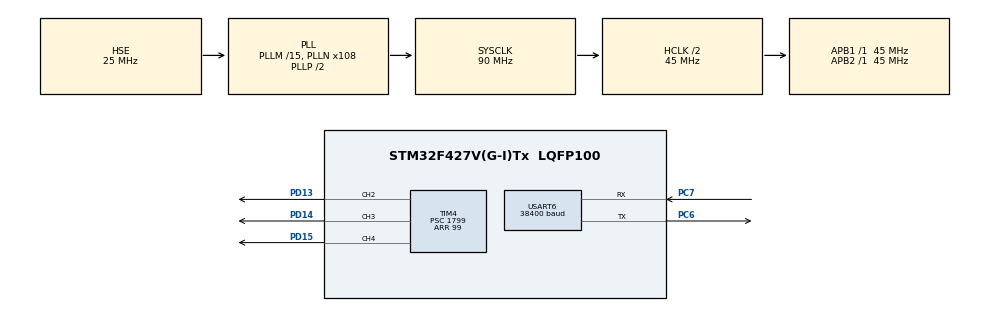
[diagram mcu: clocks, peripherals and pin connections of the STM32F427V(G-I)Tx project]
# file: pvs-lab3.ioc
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Mcu.Family=STM32F4
Mcu.Name=STM32F427V(G-I)Tx
Mcu.Package=LQFP100
NVIC.PriorityGroup=NVIC_PRIORITYGROUP_4
NVIC.USART6_IRQn=true\:0\:0\:false\:false\:true\:true\:true\:true
PC6.Mode=Asynchronous
PC6.Signal=USART6_TX
PC7.Mode=Asynchronous
PC7.Signal=USART6_RX
PD13.Signal=S_TIM4_CH2
PD14.Signal=S_TIM4_CH3
PD15.Signal=S_TIM4_CH4
PH0/OSC_IN.Mode=HSE-External-Oscillator
PH0/OSC_IN.Signal=RCC_OSC_IN
PH1/OSC_OUT.Mode=HSE-External-Oscillator
PH1/OSC_OUT.Signal=RCC_OSC_OUT
ProjectManager.HeapSize=0x200
ProjectManager.StackSize=0x400
ProjectManager.TargetToolchain=STM32CubeIDE
RCC.48MHZClocksFreq_Value=45000000
RCC.AHBCLKDivider=RCC_SYSCLK_DIV2
RCC.AHBFreq_Value=45000000
RCC.APB1Freq_Value=45000000
RCC.APB1TimFreq_Value=45000000
RCC.APB2Freq_Value=45000000
RCC.APB2TimFreq_Value=45000000
RCC.CortexFreq_Value=45000000
RCC.HCLKFreq_Value=45000000
RCC.HSE_VALUE=25000000
RCC.HSI_VALUE=16000000
RCC.LSE_VALUE=32768
RCC.PLLM=15
RCC.PLLN=108
RCC.PLLSourceVirtual=RCC_PLLSOURCE_HSE
RCC.SYSCLKFreq_VALUE=90000000
RCC.SYSCLKSource=RCC_SYSCLKSOURCE_PLLCLK
RCC.VCOOutputFreq_Value=180000000
SH.S_TIM4_CH2.0=TIM4_CH2,PWM Generation2 CH2
SH.S_TIM4_CH3.0=TIM4_CH3,PWM Generation3 CH3
SH.S_TIM4_CH4.0=TIM4_CH4,PWM Generation4 CH4
TIM4.Channel-PWM\ Generation2\ CH2=TIM_CHANNEL_2
TIM4.Channel-PWM\ Generation3\ CH3=TIM_CHANNEL_3
TIM4.Channel-PWM\ Generation4\ CH4=TIM_CHANNEL_4
TIM4.Period=99
TIM4.Prescaler=1799
USART6.BaudRate=38400
USART6.VirtualMode=VM_ASYNC
board=custom

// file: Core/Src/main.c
/* USER CODE BEGIN Header */
/**
  ******************************************************************************
  * @file           : main.c
  * @brief          : Main program body
  ******************************************************************************
  * @attention
  *
  * Copyright (c) 2025 STMicroelectronics.
  * All rights reserved.
  *
  * This software is licensed under terms that can be found in the LICENSE file
  * in the root directory of this software component.
  * If no LICENSE file comes with this software, it is provided AS-IS.
  *
  ******************************************************************************
  */
/* USER CODE END Header */
#include "main.h"
#include "tim.h"
#include "usart.h"
#include "gpio.h"

/* USER CODE BEGIN Includes */
#include "stm32_io.h"
#include "pult.h"
/* USER CODE END Includes */

void SystemClock_Config(void);

int main(void)
{

  /* MCU Configuration--------------------------------------------------------*/

  /* Reset of all peripherals, Initializes the Flash interface and the Systick. */
  HAL_Init();

  /* Configure the system clock */
  SystemClock_Config();

  /* Initialize all configured peripherals */
  MX_GPIO_Init();
  MX_TIM4_Init();
  MX_USART6_UART_Init();
  /* USER CODE BEGIN 2 */
  HAL_TIM_PWM_Start(&htim4, TIM_CHANNEL_2);
  HAL_TIM_PWM_Start(&htim4, TIM_CHANNEL_3);
  HAL_TIM_PWM_Start(&htim4, TIM_CHANNEL_4);
  char c;
  start_receive_char_it();
  /* USER CODE END 2 */

  /* Infinite loop */
  /* USER CODE BEGIN WHILE */
  while (1) {
    if (try_get_received_char((uint8_t*) &c)) {
      start_receive_char_it();
      pult_execute(c);
    }
    /* USER CODE END WHILE */

  }
}

void SystemClock_Config(void)
{
  RCC_OscInitTypeDef RCC_OscInitStruct = {0};
  RCC_ClkInitTypeDef RCC_ClkInitStruct = {0};

  /** Configure the main internal regulator output voltage
  */
  __HAL_RCC_PWR_CLK_ENABLE();
  __HAL_PWR_VOLTAGESCALING_CONFIG(PWR_REGULATOR_VOLTAGE_SCALE3);

  /** Initializes the RCC Oscillators according to the specified parameters
  * in the RCC_OscInitTypeDef structure.
  */
  RCC_OscInitStruct.OscillatorType = RCC_OSCILLATORTYPE_HSE;
  RCC_OscInitStruct.HSEState = RCC_HSE_ON;
  RCC_OscInitStruct.PLL.PLLState = RCC_PLL_ON;
  RCC_OscInitStruct.PLL.PLLSource = RCC_PLLSOURCE_HSE;
  RCC_OscInitStruct.PLL.PLLM = 15;
  RCC_OscInitStruct.PLL.PLLN = 108;
  RCC_OscInitStruct.PLL.PLLP = RCC_PLLP_DIV2;
  RCC_OscInitStruct.PLL.PLLQ = 4;
  if (HAL_RCC_OscConfig(&RCC_OscInitStruct) != HAL_OK)
  {
    Error_Handler();
  }

  /** Activate the Over-Drive mode
  */
  if (HAL_PWREx_EnableOverDrive() != HAL_OK)
  {
    Error_Handler();
  }

  /** Initializes the CPU, AHB and APB buses clocks
  */
  RCC_ClkInitStruct.ClockType = RCC_CLOCKTYPE_HCLK|RCC_CLOCKTYPE_SYSCLK
                              |RCC_CLOCKTYPE_PCLK1|RCC_CLOCKTYPE_PCLK2;
  RCC_ClkInitStruct.SYSCLKSource = RCC_SYSCLKSOURCE_PLLCLK;
  RCC_ClkInitStruct.AHBCLKDivider = RCC_SYSCLK_DIV2;
  RCC_ClkInitStruct.APB1CLKDivider = RCC_HCLK_DIV1;
  RCC_ClkInitStruct.APB2CLKDivider = RCC_HCLK_DIV1;

  if (HAL_RCC_ClockConfig(&RCC_ClkInitStruct, FLASH_LATENCY_1) != HAL_OK)
  {
    Error_Handler();
  }
}

void Error_Handler(void)
{
  __disable_irq();
  while (1)
  {
  }
}
